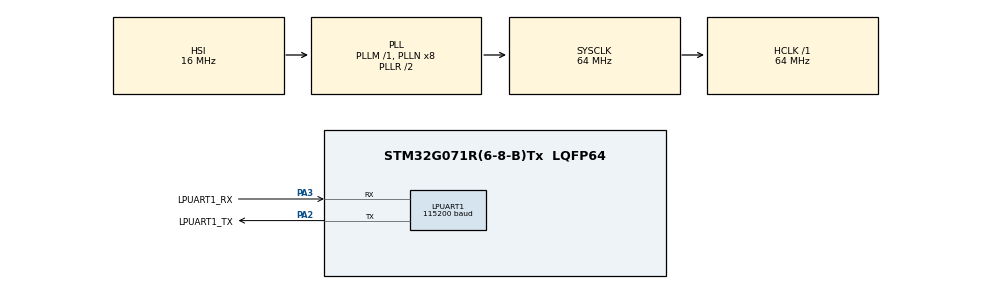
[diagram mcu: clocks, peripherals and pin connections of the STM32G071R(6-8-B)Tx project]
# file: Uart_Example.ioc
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Dma.LPUART1_RX.0.Direction=DMA_PERIPH_TO_MEMORY
Dma.LPUART1_RX.0.EventEnable=DISABLE
Dma.LPUART1_RX.0.Instance=DMA1_Channel1
Dma.LPUART1_RX.0.MemDataAlignment=DMA_MDATAALIGN_BYTE
Dma.LPUART1_RX.0.MemInc=DMA_MINC_ENABLE
Dma.LPUART1_RX.0.Mode=DMA_NORMAL
Dma.LPUART1_RX.0.PeriphDataAlignment=DMA_PDATAALIGN_BYTE
Dma.LPUART1_RX.0.PeriphInc=DMA_PINC_DISABLE
Dma.LPUART1_RX.0.Polarity=HAL_DMAMUX_REQ_GEN_RISING
Dma.LPUART1_RX.0.Priority=DMA_PRIORITY_LOW
Dma.LPUART1_RX.0.RequestNumber=1
Dma.LPUART1_RX.0.SignalID=NONE
Dma.LPUART1_RX.0.SyncEnable=DISABLE
Dma.LPUART1_RX.0.SyncPolarity=HAL_DMAMUX_SYNC_NO_EVENT
Dma.LPUART1_RX.0.SyncRequestNumber=1
Dma.LPUART1_RX.0.SyncSignalID=NONE
Dma.LPUART1_TX.1.Direction=DMA_MEMORY_TO_PERIPH
Dma.LPUART1_TX.1.EventEnable=DISABLE
Dma.LPUART1_TX.1.Instance=DMA1_Channel2
Dma.LPUART1_TX.1.MemDataAlignment=DMA_MDATAALIGN_BYTE
Dma.LPUART1_TX.1.MemInc=DMA_MINC_ENABLE
Dma.LPUART1_TX.1.Mode=DMA_NORMAL
Dma.LPUART1_TX.1.PeriphDataAlignment=DMA_PDATAALIGN_BYTE
Dma.LPUART1_TX.1.PeriphInc=DMA_PINC_DISABLE
Dma.LPUART1_TX.1.Polarity=HAL_DMAMUX_REQ_GEN_RISING
Dma.LPUART1_TX.1.Priority=DMA_PRIORITY_LOW
Dma.LPUART1_TX.1.RequestNumber=1
Dma.LPUART1_TX.1.SignalID=NONE
Dma.LPUART1_TX.1.SyncEnable=DISABLE
Dma.LPUART1_TX.1.SyncPolarity=HAL_DMAMUX_SYNC_NO_EVENT
Dma.LPUART1_TX.1.SyncRequestNumber=1
Dma.LPUART1_TX.1.SyncSignalID=NONE
Dma.Request0=LPUART1_RX
Dma.Request1=LPUART1_TX
LPUART1.BaudRate=115200
LPUART1.WordLength=UART_WORDLENGTH_8B
Mcu.Family=STM32G0
Mcu.Name=STM32G071R(6-8-B)Tx
Mcu.Package=LQFP64
NVIC.DMA1_Channel1_IRQn=true\:0\:0\:false\:false\:true\:false\:true
NVIC.DMA1_Channel2_3_IRQn=true\:0\:0\:false\:false\:true\:false\:true
NVIC.USART3_4_LPUART1_IRQn=true\:1\:0\:true\:false\:true\:true\:true
PA13.GPIO_Label=TMS
PA13.Mode=Serial_Wire
PA13.Signal=SYS_SWDIO
PA14-BOOT0.GPIO_Label=TCK
PA14-BOOT0.Mode=Serial_Wire
PA14-BOOT0.Signal=SYS_SWCLK
PA2.GPIO_Label=LPUART1_TX
PA2.Mode=Asynchronous
PA2.Signal=LPUART1_TX
PA3.GPIO_Label=LPUART1_RX
PA3.Mode=Asynchronous
PA3.Signal=LPUART1_RX
PC13.Mode=SYS_WakeUp1
PC13.Signal=SYS_WKUP2
PC14-OSC32_IN\ (PC14).Mode=LSE-External-Oscillator
PC14-OSC32_IN\ (PC14).Signal=RCC_OSC32_IN
PC15-OSC32_OUT\ (PC15).Mode=LSE-External-Oscillator
PC15-OSC32_OUT\ (PC15).Signal=RCC_OSC32_OUT
PF0-OSC_IN\ (PF0).GPIO_Label=MCO
PF0-OSC_IN\ (PF0).Mode=HSE-External-Clock-Source
PF0-OSC_IN\ (PF0).Signal=RCC_OSC_IN
ProjectManager.HeapSize=0x200
ProjectManager.StackSize=0x400
ProjectManager.TargetToolchain=MDK-ARM V5
RCC.ADCFreq_Value=64000000
RCC.AHBFreq_Value=64000000
RCC.CortexFreq_Value=64000000
RCC.EXTERNAL_CLOCK_VALUE=12288000
RCC.HCLKFreq_Value=64000000
RCC.HSE_VALUE=8000000
RCC.HSI_VALUE=16000000
RCC.SYSCLKFreq_VALUE=64000000
RCC.SYSCLKSource=RCC_SYSCLKSOURCE_PLLCLK
RCC.VCOOutputFreq_Value=128000000
board=NUCLEO-G071RB

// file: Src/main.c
/* USER CODE BEGIN Header */
/**
  ******************************************************************************
  * @file           : main.c
  * @brief          : Main program body
  ******************************************************************************
  * @attention
  *
  * <h2><center>&copy; Copyright (c) 2019 STMicroelectronics.
  * All rights reserved.</center></h2>
  *
  * This software component is licensed by ST under BSD 3-Clause license,
  * the "License"; You may not use this file except in compliance with the
  * License. You may obtain a copy of the License at:
  *                        opensource.org/licenses/BSD-3-Clause
  *
  ******************************************************************************
  */
/* USER CODE END Header */

#include "main.h"
#include "dma.h"
#include "usart.h"
#include "gpio.h"

extern UART_HandleTypeDef hlpuart1;
DataFromUart S_Data_From_Uart;
void SystemClock_Config(void);

int main(void)
{
  uint8_t aTxStartMessage[] = "\r\n****UART-Hyperterminal communication Test ****\r\n";
  HAL_Init();
  SystemClock_Config();
  MX_GPIO_Init();
  MX_DMA_Init();
  MX_LPUART1_UART_Init();
  printf("\n\r UART Printf Example: retarget the C library printf function to the UART\n\r");
#if defined (UART_POLL)

    HAL_UART_Transmit(&hlpuart1, aTxStartMessage, sizeof(aTxStartMessage) - 1, 100);

#elif defined (UART_INIT)

    HAL_UART_Transmit_IT(&hlpuart1, aTxStartMessage, sizeof(aTxStartMessage) - 1);
    HAL_UART_Receive_IT(&hlpuart1, S_Data_From_Uart.S_ReceiveBuff, UART_RX_SIZEOF);

#elif defined (UART_DMA)

    HAL_UART_Transmit_DMA(&hlpuart1,aTxStartMessage,sizeof(aTxStartMessage) - 1);
		HAL_UART_Receive_DMA(&hlpuart1, S_Data_From_Uart.S_ReceiveBuff, UART_RX_SIZEOF);

#endif

    while (1)
    {
#if defined (UART_POLL)

        if(HAL_UART_Receive(&hlpuart1, S_Data_From_Uart.S_ReceiveBuff, UART_RX_SIZEOF, 200) == HAL_OK)
        {
            HAL_UART_Transmit(&hlpuart1, S_Data_From_Uart.S_ReceiveBuff, sizeof(S_Data_From_Uart.S_ReceiveBuff), 100);
        }
        //HAL_Delay(200);
#elif defined (UART_INIT)
        if(S_Data_From_Uart.S_DataReceiveFlag == 1)
        {
					  S_Data_From_Uart.S_DataReceiveFlag = 0;
            HAL_UART_Transmit_IT(&hlpuart1, S_Data_From_Uart.S_ReceiveBuff, sizeof(S_Data_From_Uart.S_ReceiveBuff));
					  printf("\n\r");
            HAL_UART_Receive_IT(&hlpuart1, S_Data_From_Uart.S_ReceiveBuff, UART_RX_SIZEOF);

        }

#elif defined (UART_DMA)

				 if(S_Data_From_Uart.S_DataReceiveFlag == 1)
				 {
				   S_Data_From_Uart.S_DataReceiveFlag = 0;
					 HAL_UART_Transmit_DMA(&hlpuart1, S_Data_From_Uart.S_ReceiveBuff, sizeof(S_Data_From_Uart.S_ReceiveBuff));
					 HAL_UART_Receive_DMA(&hlpuart1, S_Data_From_Uart.S_ReceiveBuff, UART_RX_SIZEOF);
				 }

#endif
    }
}

void SystemClock_Config(void)
{
  RCC_OscInitTypeDef RCC_OscInitStruct = {0};
  RCC_ClkInitTypeDef RCC_ClkInitStruct = {0};
  RCC_PeriphCLKInitTypeDef PeriphClkInit = {0};

  /** Configure the main internal regulator output voltage
  */
  HAL_PWREx_ControlVoltageScaling(PWR_REGULATOR_VOLTAGE_SCALE1);
  /** Initializes the CPU, AHB and APB busses clocks
  */
  RCC_OscInitStruct.OscillatorType = RCC_OSCILLATORTYPE_HSI;
  RCC_OscInitStruct.HSIState = RCC_HSI_ON;
  RCC_OscInitStruct.HSIDiv = RCC_HSI_DIV1;
  RCC_OscInitStruct.HSICalibrationValue = RCC_HSICALIBRATION_DEFAULT;
  RCC_OscInitStruct.PLL.PLLState = RCC_PLL_ON;
  RCC_OscInitStruct.PLL.PLLSource = RCC_PLLSOURCE_HSI;
  RCC_OscInitStruct.PLL.PLLM = RCC_PLLM_DIV1;
  RCC_OscInitStruct.PLL.PLLN = 8;
  RCC_OscInitStruct.PLL.PLLP = RCC_PLLP_DIV2;
  RCC_OscInitStruct.PLL.PLLQ = RCC_PLLQ_DIV2;
  RCC_OscInitStruct.PLL.PLLR = RCC_PLLR_DIV2;
  if (HAL_RCC_OscConfig(&RCC_OscInitStruct) != HAL_OK)
  {
    Error_Handler();
  }
  /** Initializes the CPU, AHB and APB busses clocks
  */
  RCC_ClkInitStruct.ClockType = RCC_CLOCKTYPE_HCLK|RCC_CLOCKTYPE_SYSCLK
                              |RCC_CLOCKTYPE_PCLK1;
  RCC_ClkInitStruct.SYSCLKSource = RCC_SYSCLKSOURCE_PLLCLK;
  RCC_ClkInitStruct.AHBCLKDivider = RCC_SYSCLK_DIV1;
  RCC_ClkInitStruct.APB1CLKDivider = RCC_HCLK_DIV1;

  if (HAL_RCC_ClockConfig(&RCC_ClkInitStruct, FLASH_LATENCY_2) != HAL_OK)
  {
    Error_Handler();
  }
  /** Initializes the peripherals clocks
  */
  PeriphClkInit.PeriphClockSelection = RCC_PERIPHCLK_LPUART1;
  PeriphClkInit.Lpuart1ClockSelection = RCC_LPUART1CLKSOURCE_PCLK1;
  if (HAL_RCCEx_PeriphCLKConfig(&PeriphClkInit) != HAL_OK)
  {
    Error_Handler();
  }
}

/* USER CODE BEGIN 4 */
void HAL_UART_TxCpltCallback(UART_HandleTypeDef *huart)
{
    if(huart->Instance == LPUART1)
    {
        printf("Tx Transfer completed callback\r\n");
    }

}

void HAL_UART_RxCpltCallback(UART_HandleTypeDef *huart)
{
    if(huart->Instance == LPUART1)
    {
        S_Data_From_Uart.S_DataReceiveFlag = 1;
        printf("Rx Transfer completed callback\r\n");
    }
}
/* USER CODE END 4 */

void Error_Handler(void)
{
}

/************************ (C) COPYRIGHT STMicroelectronics *****END OF FILE****/
